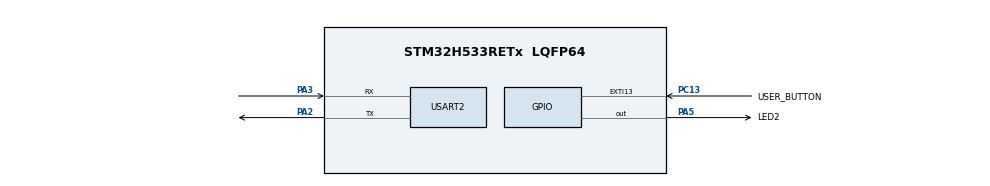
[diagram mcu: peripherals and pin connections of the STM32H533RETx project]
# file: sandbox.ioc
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BOOTPATH.BootPathName=LEGACY
BOOTPATH.UserSelectedBootPath=LEGACY
CORTEX_M33_NS.userName=CORTEX_M33
GPDMA1.IPHANDLE_GPDMACH0-SIMPLEREQUEST_GPDMACH0=__NULL
GPDMA1.REQUEST_GPDMACH0=GPDMA1_REQUEST_USART2_TX
GPDMA1.SRCINC_GPDMACH0=DMA_SINC_INCREMENTED
Mcu.Family=STM32H5
Mcu.Name=STM32H533RETx
Mcu.Package=LQFP64
NVIC.EXTI13_IRQn=true\:0\:0\:false\:false\:true\:true\:true\:true
NVIC.GPDMA1_Channel0_IRQn=true\:0\:0\:false\:false\:true\:false\:true\:true
NVIC.PriorityGroup=NVIC_PRIORITYGROUP_4
PA2.Mode=Asynchronous
PA2.Signal=USART2_TX
PA3.Mode=Asynchronous
PA3.Signal=USART2_RX
PA5.GPIO_Label=LED2
PA5.Signal=GPIO_Output
PC13.GPIO_Label=USER_BUTTON
PC13.Signal=GPXTI13
PH0-OSC_IN(PH0).Mode=HSE-External-Oscillator
PH0-OSC_IN(PH0).Signal=RCC_OSC_IN
PH1-OSC_OUT(PH1).Mode=HSE-External-Oscillator
PH1-OSC_OUT(PH1).Signal=RCC_OSC_OUT
ProjectManager.HeapSize=0x200
ProjectManager.StackSize=0x400
ProjectManager.TargetToolchain=CMake
RCC.ADCFreq_Value=250000000
RCC.AHBFreq_Value=250000000
RCC.APB1Freq_Value=250000000
RCC.APB1TimFreq_Value=250000000
RCC.APB2Freq_Value=250000000
RCC.APB2TimFreq_Value=250000000
RCC.APB3Freq_Value=250000000
RCC.CSI_VALUE=4000000
RCC.CortexFreq_Value=250000000
RCC.EPOD_VALUE=24000000
RCC.HCLKFreq_Value=250000000
RCC.HSE_VALUE=24000000
RCC.HSI48_VALUE=48000000
RCC.HSI_VALUE=64000000
RCC.LSE_VALUE=32768
RCC.LSIRC_VALUE=32000
RCC.PLLM=12
RCC.PLLN=250
RCC.PLLSourceVirtual=RCC_PLL1_SOURCE_HSE
RCC.SYSCLKFreq_VALUE=250000000
RCC.SYSCLKSource=RCC_SYSCLKSOURCE_PLLCLK
RCC.USBFreq_Value=48000000
RCC.VCOOutputFreq_Value=500000000
USART2.VirtualMode-Asynchronous=VM_ASYNC
VP_BOOTPATH_VS_BOOTPATH.Mode=BP_Activate
VP_CORTEX_M33_NS_VS_Hclk.Mode=Hclk_Mode
VP_GPDMA1_VS_GPDMACH0.Mode=SIMPLEREQUEST_GPDMACH0
VP_MEMORYMAP_VS_MEMORYMAP.Mode=CurAppReg
VP_PWR_VS_DBSignals.Mode=DisableDeadBatterySignals
VP_PWR_VS_LPOM.Mode=PowerOptimisation
VP_PWR_VS_SECSignals.Mode=Security/Privilege
board=NUCLEO-H533RE

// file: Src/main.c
/* USER CODE BEGIN Header */
/**
  ******************************************************************************
  * @file           : main.c
  * @brief          : Main program body
  ******************************************************************************
  * @attention
  *
  * Copyright (c) 2025 STMicroelectronics.
  * All rights reserved.
  *
  * This software is licensed under terms that can be found in the LICENSE file
  * in the root directory of this software component.
  * If no LICENSE file comes with this software, it is provided AS-IS.
  *
  ******************************************************************************
  */
/* USER CODE END Header */
#include "main.h"
#include "gpdma.h"
#include "usart.h"
#include "gpio.h"

/* USER CODE BEGIN Includes */
#include "trace_log.h"
#include "port.h"

/* USER CODE END Includes */

void SystemClock_Config(void);

int main(void)
{

  /* MCU Configuration--------------------------------------------------------*/

  /* Reset of all peripherals, Initializes the Flash interface and the Systick. */
  HAL_Init();

  /* Disable the internal Pull-Up in Dead Battery pins of UCPD peripheral */
  LL_PWR_DisableUCPDDeadBattery();

  /* Configure the system clock */
  SystemClock_Config();

  /* USER CODE BEGIN SysInit */
  port_dwt_init();
  /* USER CODE END SysInit */

  /* Initialize all configured peripherals */
  MX_GPIO_Init();
  MX_GPDMA1_Init();
  MX_USART2_UART_Init();
  /* USER CODE BEGIN 2 */

  trace_log_init();
  TRACE_LOG(TID_MAIN, TL_STARTUP, "System initialized");

  /* USER CODE END 2 */

  /* Infinite loop */
  while (1)
  {

  }
}

void SystemClock_Config(void)
{
  LL_FLASH_SetLatency(LL_FLASH_LATENCY_5);
  while(LL_FLASH_GetLatency()!= LL_FLASH_LATENCY_5)
  {
  }

  LL_PWR_SetRegulVoltageScaling(LL_PWR_REGU_VOLTAGE_SCALE0);
  while (LL_PWR_IsActiveFlag_VOS() == 0)
  {
  }
  LL_RCC_HSE_Enable();

   /* Wait till HSE is ready */
  while(LL_RCC_HSE_IsReady() != 1)
  {
  }

  LL_RCC_PLL1_SetSource(LL_RCC_PLL1SOURCE_HSE);
  LL_RCC_PLL1_SetVCOInputRange(LL_RCC_PLLINPUTRANGE_2_4);
  LL_RCC_PLL1_SetVCOOutputRange(LL_RCC_PLLVCORANGE_WIDE);
  LL_RCC_PLL1_SetM(12);
  LL_RCC_PLL1_SetN(250);
  LL_RCC_PLL1_SetP(2);
  LL_RCC_PLL1_SetQ(2);
  LL_RCC_PLL1_SetR(2);
  LL_RCC_PLL1P_Enable();
  LL_RCC_PLL1_Enable();

   /* Wait till PLL is ready */
  while(LL_RCC_PLL1_IsReady() != 1)
  {
  }

  LL_RCC_SetSysClkSource(LL_RCC_SYS_CLKSOURCE_PLL1);

   /* Wait till System clock is ready */
  while(LL_RCC_GetSysClkSource() != LL_RCC_SYS_CLKSOURCE_STATUS_PLL1)
  {
  }

  LL_RCC_SetAHBPrescaler(LL_RCC_SYSCLK_DIV_1);
  LL_RCC_SetAPB1Prescaler(LL_RCC_APB1_DIV_1);
  LL_RCC_SetAPB2Prescaler(LL_RCC_APB2_DIV_1);
  LL_RCC_SetAPB3Prescaler(LL_RCC_APB3_DIV_1);
  LL_SetSystemCoreClock(250000000);

   /* Update the time base */
  if (HAL_InitTick (TICK_INT_PRIORITY) != HAL_OK)
  {
    Error_Handler();
  }
}

void Error_Handler(void)
{
  __disable_irq();
  while (1)
  {
  }
}
